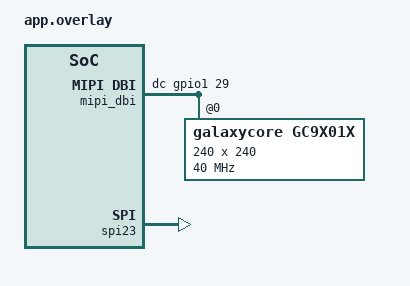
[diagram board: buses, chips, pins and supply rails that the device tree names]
/*
 * XIAO nRF54LM20B -- Pin Multiplexing demo 6: SPI (GC9A01 240x240 round LCD)
 * ----------------------------------------------------------------------------
 * GC9X01X 240x240 round LCD on spi23:
 *   SPI23:  SCK=P1.04/D8  MOSI=P1.06/D10  MISO=P1.05/D9
 *   CS:     P1.31/D1  (SPI bus software CS)
 *   DC:     P1.29/D3  (Data/Command select, on the MIPI DBI node)
 *
 * In Zephyr 4.x the GC9X01X driver uses the MIPI DBI interface: the display
 * node is a child of a zephyr,mipi-dbi-spi node, which references the SPI
 * controller via spi-dev.
 *
 * 20B adaptations: spi23 pinctrl (P1.4/P1.6/P1.5) is already in the board
 * DTS, so the wiki's spi23_default/sleep redefinition is dropped; only
 * status + cs-gpios are set here. The console stays on USB CDC (the wiki's
 * chosen console/rpc-uart/shell-uart on uart20, and the uart20_default/sleep
 * redefinition, are all dropped).
 *
 * SPDX-License-Identifier: Apache-2.0
 */

#include <zephyr/dt-bindings/gpio/gpio.h>
#include <zephyr/dt-bindings/display/panel.h>

/ {
	chosen {
		zephyr,display = &gc9x01x;
	};

	mipi_dbi {
		compatible = "zephyr,mipi-dbi-spi";
		spi-dev = <&spi23>;
		dc-gpios = <&gpio1 29 GPIO_ACTIVE_HIGH>;
		write-only;
		#address-cells = <1>;
		#size-cells = <0>;
		gc9x01x: gc9x01x@0 {
			compatible = "galaxycore,gc9x01x";
			reg = <0>;
			mipi-max-frequency = <40000000>;
			pixel-format = <PANEL_PIXEL_FORMAT_RGB_565>;
			display-inversion;
			width  = <240>;
			height = <240>;
			status = "okay";
		};
	};
};

&spi23 {
	status = "okay";
	/* CS P1.31 — index 0 used by the MIPI DBI driver */
	cs-gpios = <&gpio1 31 GPIO_ACTIVE_LOW>;
};
